# PIC32CM6408PL10064 device description
Architecture: CORTEX-M0PLUS; Family: PIC32CMPL; Series: PIC32CMPL10
Registers are 32-bit, read-write, reset 0x0 unless marked. A register's access mark holds for its fields unless they carry their own. Offsets are from the block's base; [hi:lo] are bit positions; lines under a group give offsets from that group; {n}, {i} and the like mark numbered series; 'fields as' and 'values as' point back to an identical list.

## AC — Analog Comparator
Instances: AC 0x42002000
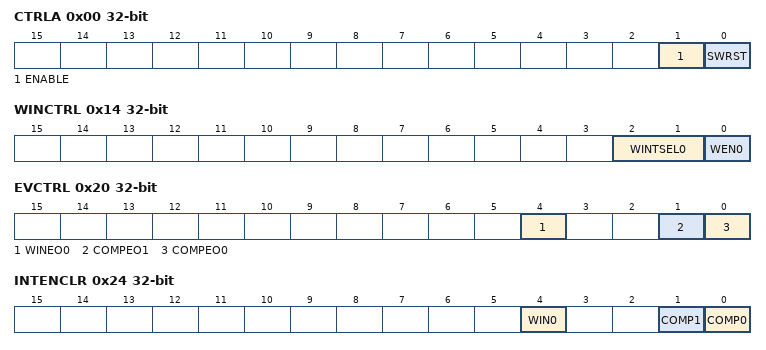
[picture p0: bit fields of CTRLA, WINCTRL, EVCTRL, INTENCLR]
0x00 CTRLA — Control A
  [1] ENABLE — Global Enable
  [0] SWRST — Software Reset
0x04 CTRLB — Control B
  [1:0] INTREF — Internal Reference Selection
    0=1V024 (Internal 1.024V reference); 1=2V048 (Internal 2.048V reference); 2=4V096 (Internal 4.096V reference); 3=2V500 (Internal 2.500V reference)
0x14 WINCTRL — Window Control
  [2:1] WINTSEL0 — Window 0 Interrupt Selection
    0=ABOVE (Interrupt when the signal goes above the window); 1=INSIDE (Interrupt when the signal goes inside the window); 2=BELOW (Interrupt when the signal goes below the window); 3=OUTSIDE (Interrupt when the signal goes outside the window)
  [0] WEN0 — Window 0 Enable
0x20 EVCTRL — Event Control
  [4] WINEO0 — Window 0 Event Output Enable
  [1] COMPEO1 — Comparator 1 Event Output Enable
  [0] COMPEO0 — Comparator 0 Event Output Enable
0x24 INTENCLR (atomic clear) — Interrupt Enable Clear
  [4] WIN0 — Window 0 Interrupt Enable
  [1] COMP1 — Comparator 1 Interrupt Enable
  [0] COMP0 — Comparator 0 Interrupt Enable
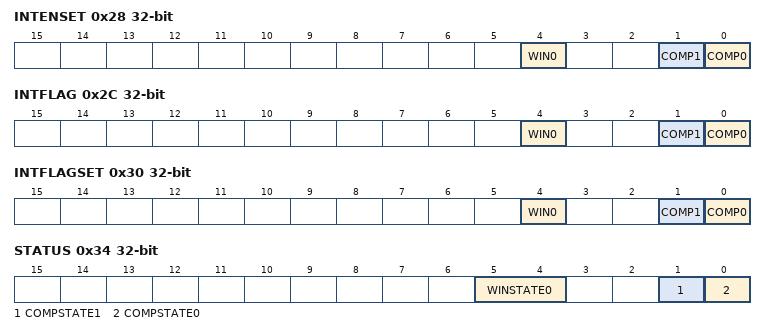
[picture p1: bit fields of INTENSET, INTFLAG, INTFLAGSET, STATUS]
0x28 INTENSET (atomic set) — Interrupt Enable Set
  fields as INTENCLR
0x2C INTFLAG (atomic clear) — Interrupt Flag Status and Clear
  [4] WIN0 — Window 0 Interrupt Flag
  [1] COMP1 — Comparator 1 Interrupt Flag
  [0] COMP0 — Comparator 0 Interrupt Flag
0x30 INTFLAGSET (atomic clear) — Interrupt Flag Set
  fields as INTFLAG
0x34 STATUS ro
  [5:4] WINSTATE0 — Window 0 State
    0=ABOVE (The input signal is above window n); 1=INSIDE (The input signal is inside window n); 2=BELOW (The input signal is below window n)
  [1] COMPSTATE1 — Comparator 1 State
  [0] COMPSTATE0 — Comparator 0 State
{0x40+0x10*i} COMP[{i}] (i=0..1) group
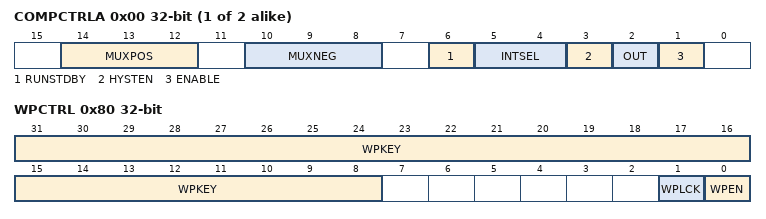
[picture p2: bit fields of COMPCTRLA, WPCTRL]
  0x00 COMPCTRLA — Comparator # Comparator Control A
    [14:12] MUXPOS — Positive Input Selection
      {v}=AINP{v} (Positive pin {v}) (v=0..3); 5=AINP5 (Positive pin 5); 6=AINP6 (Positive pin 6); 7=VDDIO2DIV10
    [10:8] MUXNEG — Negative Input Selection
      0=AINN0 (Negative pin 0); 1=AINN1 (Negative pin 1); 2=AINN2 (Negative pin 2); 7=VREFSCALE (Voltage Reference Scaler)
    [6] RUNSTDBY — Run in Standby
    [5:4] INTSEL — Interrupt Selection
      0=TOGGLE (Interrupt on comparator n output toggle); 1=RISING (Interrupt on comparator n output rising edge); 2=FALLING (Interrupt on comparator n output falling edge)
    [3] HYSTEN — Hysteresis Enable
    [2] OUT — Output Enable
    [1] ENABLE — Comparator Enable
  0x04 COMPCTRLB — Comparator # Comparator Control B
    [1:0] REFSEL — Reference Selection
      0=VDD; 1=INTVREF (Internal reference voltage, as defined by the Internal Reference Selection bit field in the Control B register (CTRLB.INTREF)); 2=EXTVREF (External reference pin)
  0x08 COMPSCALER — Comparator # Comparator Scaler
    [7:0] VALUE — Scaled Reference Voltage
0x80 WPCTRL — Write Protection Control
  [31:8] WPKEY — Write Protection Key
    0x414320=KEY (Allow writes to the WPCTRL register)
  [1] WPLCK — Write Protection Lock
  [0] WPEN — Write Protection Enable

## CCL — Configurable Custom Logic
Instances: CCL 0x42002400
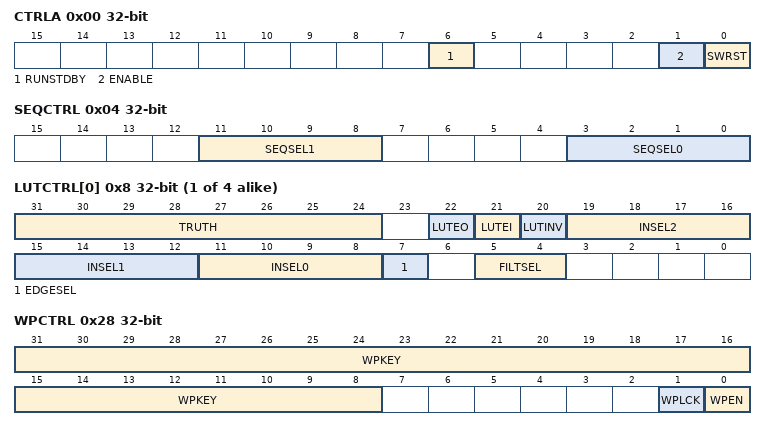
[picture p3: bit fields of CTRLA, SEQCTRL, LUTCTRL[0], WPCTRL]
0x00 CTRLA — Control A
  [6] RUNSTDBY — Run in Standby
  [1] ENABLE
  [0] SWRST — Software Reset
0x04 SEQCTRL — Sequential Control
  [11:8] SEQSEL1 — Sequential Selection 1
    0=DISABLE (Sequential logic is disabled); 1=DFF (D flip-flop); 2=JK (JK flip-flop); 3=LATCH (D latch); 4=RS (RS latch)
  [3:0] SEQSEL0 — Sequential Selection 0
    values as SEQSEL1
{0x8+4i} LUTCTRL[{i}] (i=0..3) — LUT Control #
  [31:24] TRUTH — Truth Table
  [22] LUTEO — LUT Event Output Enable
  [21] LUTEI — LUT Event Input Enable
  [20] LUTINV — LUT Inverted Event Input Enable
  [19:16] INSEL2 — LUT Input 2 Source Selection
    0=MASK (Masked input); 1=FEEDBACK (Feedback input source); 2=LINK (Linked LUT input source); 3=EVENT (Event input source); 4=IO (I/O pin input source); 5=AC (AC input source: CMP[0] (LUT0) / CMP[1] (LUT1) / CMP[0] (LUT2) / CMP[1] (LUT3)); 6=TC (TC input source: TC0 (LUT0) / TC1 (LUT1) / TC2 (LUT2) / TC0 (LUT3)); 8=TCC (TCC input source: TCC0); 9=SERCOM (SERCOM input source: SERCOM0 (LUT0) / SERCOM1 (LUT1) / SERCOM0 (LUT2) / SERCOM1 (LUT3)); 11=ASYNCEVENT (Asynchronous event input source)
  [15:12] INSEL1 — LUT Input 1 Source Selection
    values as INSEL2
  [11:8] INSEL0 — LUT Input 0 Source Selection
    values as INSEL2
  [7] EDGESEL — Edge Selection
  [5:4] FILTSEL — Filter Selection
    0=DISABLE (Filter disabled); 1=SYNCH (Synchronizer enabled); 2=FILTER (Filter enabled)
0x28 WPCTRL — Write Protection Control
  [31:8] WPKEY — Write Protection Key
    0x43434C=KEY (Allow writes to the WPCTRL register)
  [1] WPLCK — Write Protection Lock
  [0] WPEN — Write Protection Enable
